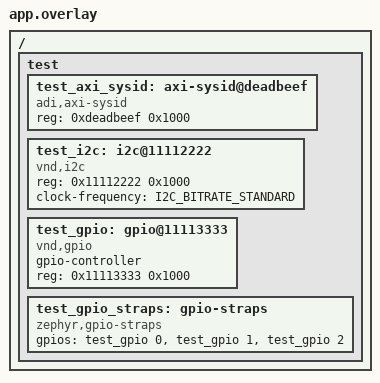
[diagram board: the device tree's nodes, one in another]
/*
 * Copyright (c) 2026 Analog Devices, Inc.
 *
 * SPDX-License-Identifier: Apache-2.0
 *
 * Application overlay for testing driver builds
 *
 * Names in this file should be chosen in a way that won't conflict
 * with real-world devicetree nodes, to allow these tests to run on
 * (and be extended to test) real hardware.
 */

#include <zephyr/dt-bindings/i2c/i2c.h>

/ {
	test {
		#address-cells = <1>;
		#size-cells = <1>;

		test_axi_sysid: axi-sysid@deadbeef {
			compatible = "adi,axi-sysid";
			reg = <0xdeadbeef 0x1000>;
			status = "okay";
		};

		test_i2c: i2c@11112222 {
			#address-cells = <1>;
			#size-cells = <0>;
			compatible = "vnd,i2c";
			reg = <0x11112222 0x1000>;
			status = "okay";
			clock-frequency = <I2C_BITRATE_STANDARD>;

#include "i2c.dtsi"
		};

		test_gpio: gpio@11113333 {
			compatible = "vnd,gpio";
			gpio-controller;
			reg = <0x11113333 0x1000>;
			#gpio-cells = <0x2>;
			status = "okay";
		};

		test_gpio_straps: gpio-straps {
			compatible = "zephyr,gpio-straps";
			gpios = <&test_gpio 0 0>, <&test_gpio 1 0>, <&test_gpio 2 0>;
			status = "okay";
		};
	};
};
